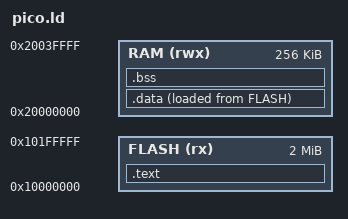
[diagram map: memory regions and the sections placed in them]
MEMORY
{
    FLASH (rx) : ORIGIN = 0x10000000, LENGTH = 2M
    RAM (rwx) : ORIGIN = 0x20000000, LENGTH = 256K
}

SECTIONS
{
    .text : {
        *(.text*)
        *(.rodata*)
    } > FLASH

    .data : {
        *(.data*)
    } > RAM AT > FLASH

    .bss : {
        *(.bss*)
    } > RAM

    _stack_top = ORIGIN(RAM) + LENGTH(RAM);
}
